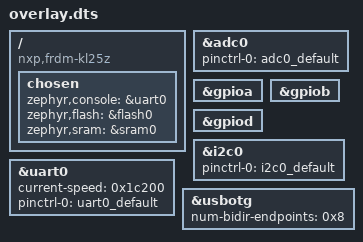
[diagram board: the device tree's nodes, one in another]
/ {
	compatible = "nxp,frdm-kl25z", "nxp,kl25z", "nxp,mkl25z4";
	chosen {
		zephyr,console = &uart0;
		zephyr,flash = &flash0;
		zephyr,sram = &sram0;
	};
};
&adc0{
	status = "okay";
	pinctrl-0 = < &adc0_default >;
	pinctrl-names = "default";
};
&gpioa{
	status = "okay";
};
&gpiob{
	status = "okay";
};
&gpiod{
	status = "okay";
};
&i2c0{
	status = "okay";
	pinctrl-0 = < &i2c0_default >;
	pinctrl-names = "default";
};
&uart0{
	status = "okay";
	current-speed = < 0x1c200 >;
	pinctrl-0 = < &uart0_default >;
	pinctrl-names = "default";
};
&usbotg{
	num-bidir-endpoints = < 0x8 >;
	status = "okay";
};
